# STM32U031 register map
File version: 1.0
CPU: CM0+ r0p1, little endian, MPU, no FPU, 4 interrupt priority bits
Registers are 32-bit, read-write, reset 0x0 unless marked. A register's access mark holds for its fields unless they carry their own. Offsets are from the block's base; [hi:lo] are bit positions; {n}, {i} and the like mark numbered series.

## DMAMUX — DMAMUX address block description
Base 0x40020800
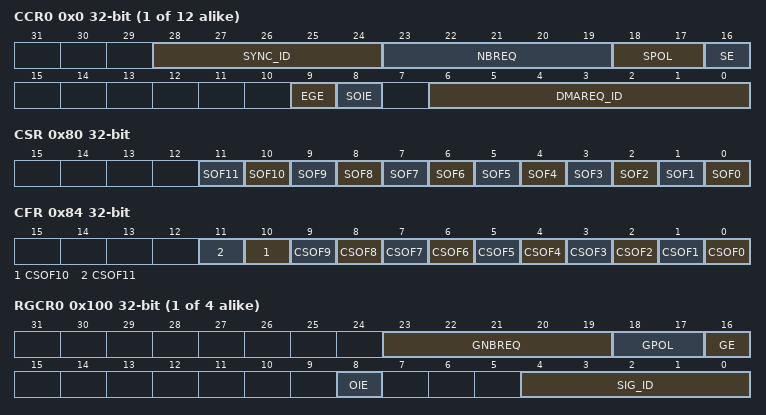
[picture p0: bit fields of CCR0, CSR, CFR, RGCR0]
{0x0+4i} CCR{i} (i=0..11) — DMA Multiplexer Channel {i} Control register
  [28:24] SYNC_ID — Synchronization identification Selects the synchronization input (see Table137: DMAMUX: assignment of synchronization inputs to resources).
  [23:19] NBREQ — Number of DMA requests minus 1 to forward Defines the number of DMA requests to forward to the DMA controller after a synchronization event, and/or the number of DMA requests before an output event is generated. This field must only be written when both SE and EGE bits are low.
  [18:17] SPOL — Synchronization polarity Defines the edge polarity of the selected synchronization input:
    0=NoEdge (No event, i.e. no synchronization nor detection); 1=RisingEdge; 2=FallingEdge; 3=BothEdges (Rising and falling edges)
  [16] SE — Synchronization enable
    0=Disabled (Synchronization disabled); 1=Enabled (Synchronization enabled)
  [9] EGE — Event generation enable
    0=Disabled (Event generation disabled); 1=Enabled (Event generation enabled)
  [8] SOIE — Synchronization overrun interrupt enable
    0=Disabled (Synchronization overrun interrupt disabled); 1=Enabled (Synchronization overrun interrupt enabled)
  [6:0] DMAREQ_ID — DMA request identification Selects the input DMA request. See the DMAMUX table about assignments of multiplexer inputs to resources.
0x80 CSR ro — DMAMUX request line multiplexer interrupt channel status register
  [n] SOF{n} (n=0..11) — Synchronization Overrun Flag {n}
    0=NoSyncEvent (No synchronization event occured on a DMA request line multiplexer channel x, while the DMA request counter value is lower than NBREQ); 1=SyncEvent (Synchronization event occured on a DMA request line multiplexer channel x, while the DMA request counter value is lower than NBREQ)
0x84 CFR wo — DMAMUX request line multiplexer interrupt clear flag register
  [n] CSOF{n} (n=0..11) write-1-clears — Synchronization Clear Overrun Flag {n}
    1=Clear synchronization flag
{0x100+4i} RGCR{i} (i=0..3) — DMAMUX request generator channel {i} configuration register
  [23:19] GNBREQ — Number of DMA requests to be generated (minus 1) Defines the number of DMA requests to be generated after a trigger event. The actual number of generated DMA requests is GNBREQ +1. Note: This field must be written only when GE bit is disabled.
  [18:17] GPOL — DMA request generator trigger polarity Defines the edge polarity of the selected trigger input
    0=NoEdge (No event, i.e. no detection nor generation); 1=RisingEdge; 2=FallingEdge; 3=BothEdges (Rising and falling edges)
  [16] GE — DMA request generator channel x enable
    0=Disabled (DMA request generation disabled); 1=Enabled (DMA request enabled)
  [8] OIE — Trigger overrun interrupt enable
    0=Disabled (Trigger overrun interrupt disabled); 1=Enabled (Trigger overrun interrupt enabled)
  [4:0] SIG_ID — Signal identification Selects the DMA request trigger input used for the channel x of the DMA request generator
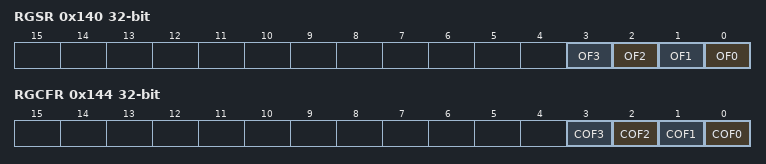
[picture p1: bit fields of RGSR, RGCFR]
0x140 RGSR ro — DMAMUX request generator interrupt status register
  [n] OF{n} (n=0..3) — Generator Overrun Flag {n}
    0=NoTrigger (No new trigger event occured on DMA request generator channel x, before the request counter underrun); 1=Trigger (New trigger event occured on DMA request generator channel x, before the request counter underrun)
0x144 RGCFR wo — DMAMUX request generator interrupt clear flag register
  [n] COF{n} (n=0..3) write-1-clears — Generator Clear Overrun Flag {n}
    1=Clear overrun flag

## GPIOA — GPIOA address block description
Base 0x50000000
Same registers: GPIOB 0x50000400, GPIOC 0x50000800, GPIOD 0x50000C00, GPIOE 0x50001000, GPIOF 0x50001400
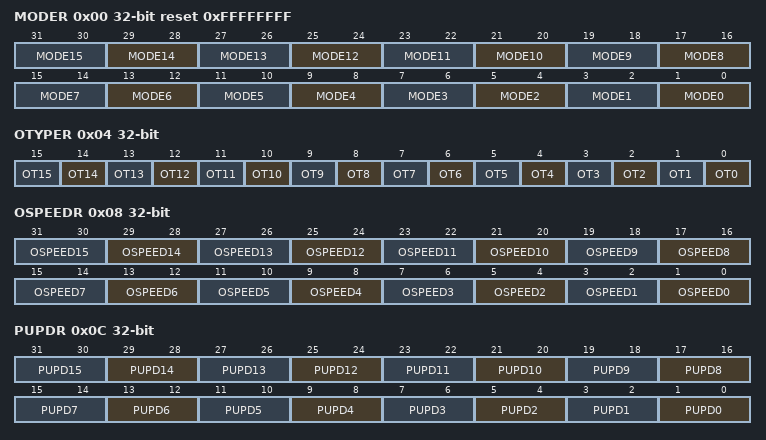
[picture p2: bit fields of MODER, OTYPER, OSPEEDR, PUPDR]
0x00 MODER reset 0xFFFFFFFF — GPIO port mode register
  [2n+1:2n] MODE{n} (n=0..15) — Port x configuration pin {n}
    0=Input mode; 1=Output (General purpose output mode); 2=Alternate function mode; 3=Analog mode
0x04 OTYPER — GPIO port output type register
  [n] OT{n} (n=0..15) — Port x configuration pin {n}
    0=PushPull (Output push-pull (reset state)); 1=OpenDrain (Output open-drain)
0x08 OSPEEDR — GPIO port output speed register
  [2n+1:2n] OSPEED{n} (n=0..15) — Port x configuration pin {n}
    0=LowSpeed; 1=MediumSpeed; 2=HighSpeed; 3=VeryHighSpeed
0x0C PUPDR — GPIO port pull-up/pull-down register
  [2n+1:2n] PUPD{n} (n=0..15) — Port x configuration pin {n}
    0=Floating (No pull-up, pull-down); 1=PullUp; 2=PullDown
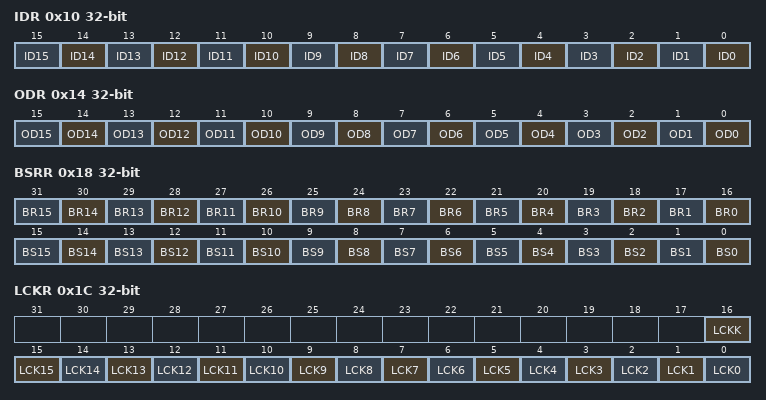
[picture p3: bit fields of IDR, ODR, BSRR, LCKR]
0x10 IDR ro (reset mask 0xFFFF0000) — GPIO port input data register
  [n] ID{n} (n=0..15) — Port input data pin {n}
    0=Low (Input is logic low); 1=High (Input is logic high)
0x14 ODR — GPIO port output data register
  [n] OD{n} (n=0..15) — Port output data pin {n}
    0=Low (Set output to logic low); 1=High (Set output to logic high)
0x18 BSRR wo — GPIO port bit set/reset register
  [n+16] BR{n} (n=0..15) — Port x reset pin {n}
    1=Resets the corresponding ODx bit
  [n] BS{n} (n=0..15) — Port x set pin {n}
    1=Set (Sets the corresponding ODx bit)
0x1C LCKR — GPIO port configuration lock register
  [16] LCKK — Lock key This bit can be read any time. It can only be modified using the lock key write sequence. LOCK key write sequence: WR LCKR[16] = 1 + LCKR[15:0] WR LCKR[16] = 0 + LCKR[15:0] WR LCKR[16] = 1 + LCKR[15:0] RD LCKR RD LCKR[16] = 1 (this read operation is optional but it confirms that the lock is active) Note: During the LOCK key write sequence, the value of LCK[15:0] must not change. Note: Any error in the lock sequence aborts the lock. Note: After the first lock sequence on any bit of the port, any read access on the LCKK bit returns 1 until the next MCU reset or peripheral reset.
    0=NotActive (Port configuration lock key not active); 1=Active (Port configuration lock key active)
  [n] LCK{n} (n=0..15) — Port x lock pin {n}
    0=Unlocked (Port configuration not locked); 1=Locked (Port configuration locked)
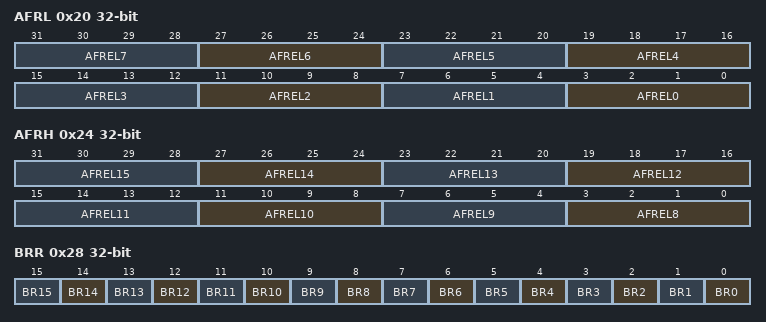
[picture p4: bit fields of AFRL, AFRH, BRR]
0x20 AFRL — GPIO alternate function low register
  [3:0] AFR{x} (x=EL0,EL1,EL2,EL3,EL4,EL5,EL6,EL7; step 4) — Alternate function selection for port x I/O pin y These bits are written by software to configure alternate function I/Os.
    {v}=AF{v} (v=0..15)
0x24 AFRH — GPIO alternate function high register
  [3:0] AFR{x} (x=EL8,EL9,EL10,EL11,EL12,EL13,EL14,EL15; step 4) — Alternate function selection for port x I/O pin y These bits are written by software to configure alternate function I/Os.
    {v}=AF{v} (v=0..15)
0x28 BRR wo — GPIO port bit reset register
  [n] BR{n} (n=0..15) — Port x reset pin {n}
    0=No action on the corresponding ODx bit; 1=Reset the ODx bit
